# CEC1712H_S2_SX register map
Vendor: Microchip Technology; Series: CEC1712H_S2_SX; File version: 0
CPU: CM4 r1p0, little endian, no MPU, 3 interrupt priority bits, 172 interrupts
Registers are 32-bit, read-write, reset 0x0 unless marked. A register's access mark holds for its fields unless they carry their own. Offsets are from the block's base; [hi:lo] are bit positions.

## VCI — The VBAT-Powered Control Interfaces with the RTC With Date and DST Adjustment as well as the Week Alarm.
Base 0x4000AE00; register names take the prefix VCI_
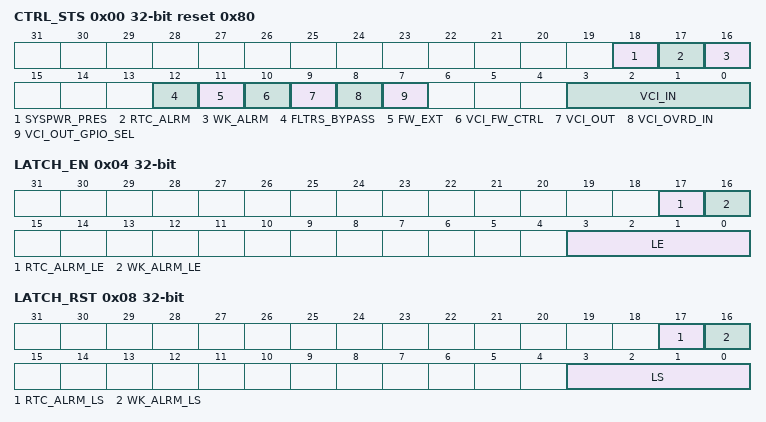
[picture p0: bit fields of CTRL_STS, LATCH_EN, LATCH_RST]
0x00 CTRL_STS reset 0x80 — VCI Register
  [18] SYSPWR_PRES — This is the System power present select bit. 1= VCI_IN3 is used as System power present. 0= VCI_IN3 is used as VCI_IN3.
  [17] RTC_ALRM — If enabled by RTC_ALRM_LE, this bit is set to 1 if the RTC Alarm signal is asserted. It is reset by writes to RTC_ALRM_LS.
  [16] WK_ALRM — If enabled by WEEK_ALRM_LE, this bit is set to 1 if the Week Alarm signal is asserted. It is reset by writes to WEEK_ALRM_LS.
  [12] FLTRS_BYPASS — The Filters Bypass bit is used to enable and disable the input filters on the VCI_IN# pins. 1=Filters disabled; 0=Filters enabled (default).
  [11] FW_EXT — This bit controls selecting between the external VBAT-Powered Control Interface inputs, or the VCI_FW_CNTRL bit output to control the VCI_OUT pin. 1=VCI_OUT is determined by the VCI_FW_CNTRL field, when VTR is active. 0=VCI_OUT is determined by the external inputs. Note: This bit used to be called GPO/nEXT. The name was changed to distinguish it from the BGPOs, which are elsewhere, and to remove a / in a bit name.
  [10] VCI_FW_CTRL — This bit can allow EC firmware to control the state of the VCI_OUT pin. For example, when VTR_PWRGD is asserted and the. FW_EXT bit is 1, clearing the VCI_FW_CNTRL bit de-asserts the active high VCI_OUT pin. BIOS must set this bit to 1 prior to setting the FW_EXT bit to 1 on power up, in order to avoid glitches on the VCI_OUT pin.
  [9] VCI_OUT — This bit provides the current status of the VCI_OUT pin.
  [8] VCI_OVRD_IN — This bit provides the current status of the VCI_OVRD_IN pin. Note: The VCI_OVRD_IN bit defaults to the state of the respective input pin.
  [7] VCI_OUT_GPIO_SEL — This bit selects the power source for GPIO outputs. 1= GPIO will be powered by VBAT power well (VCI_OUT functionality). 0= GPIO will be powered by VTR power well.
  [3:0] VCI_IN — These bits provide the latched state of the associated VCI_IN# pin, if latching is enabled or the current state of the pin if latching is not enabled. In both cases, the value is determined after the action of the VCI Polarity Register. Note: The VCI_IN[6:0]# bits default to the state of their respective input pins.
0x04 LATCH_EN — Latch Enable Register
  [17] RTC_ALRM_LE — Latch enable for the RTC Power-Up signal. 1=Enabled. Assertions of the RTC Alarm are held until the latch is reset by writing the corresponding LS bit. 0=Not Enabled. The RTC Alarm signal is not latched but passed directly to the VCI_OUT logic
  [16] WK_ALRM_LE — Latch enable for the Week Alarm Power-Up signal. 1=Enabled. Assertions of the Week Alarm are held until the latch is reset by writing the corresponding LS bit. 0=Not Enabled. The Week Alarm signal is not latched but passed directly to the VCI_OUT logic
  [3:0] LE — Latching Enables. Latching occurs after the Polarity configuration, so a VCI_INi# pin is asserted when it is '0' if VCI_IN_POL is '0', and asserted when it is '1' if VCI_IN_POL is '1'. For each bit in the field: 1=Enabled. Assertions of the VCI_INi# pin are held until the latch is reset by writing the corresponding LS bit. 0=Not Enabled. The VCI_INi# signal is not latched but passed directly to the VCI_OUT logic
0x08 LATCH_RST — Latch Resets Register
  [17] RTC_ALRM_LS — RTC Alarm Latch Reset. When this bit is written with a '1', the RTC Alarm Event latch is reset. The RTC Alarm input to the latch has priority over the Reset input Reads of this register are undefined.
  [16] WK_ALRM_LS — Week Alarm Latch Reset. When this bit is written with a '1', the Week Alarm Event latch is reset. The Week Alarm input to the latch has priority over the Reset input Reads of this register are undefined.
  [3:0] LS — Latch Resets. When a Latch Resets bit is written with a '1', the corresponding VCI_INi# latch is de-asserted ('1'). The VCI_INi# input to the latch has priority over the Latch Reset input, so firmware cannot reset the latch while the VCI_INi# pin is asserted. Firmware should sample the state of the pin in the VCI Register before attempting to reset the latch. As noted in the Latch Enable Register, the assertion level is determined by the VCI_IN_POL bit. Reads of this register are undefined.
0x0C INPUT_EN reset 0x7 — VCI Input Enable Register
  [3:0] IE — Input Enables for VCI_IN# signals. After changing the input enable for a VCI input, firmware should reset the input latch and clear any potential interrupt that may have been triggered by the input, as changing the enable may cause the internal status to change. For each bit in the field: 1=Enabled. The corresponding VCI_IN# input is not gated and toggling the pin will affect the VCI_OUT pin. 0=Not Enabled. the corresponding VCI_IN# input does not affect the VCI_OUT pin, even if the input is '0'. Unless the corresponding bit in the VCI Buffer Enable Register is 1, latches are not asserted, even if the VCI_IN# pin is low, during a VBAT power transition
0x10 HLDOFF_CNT — Holdoff Count Register
  [7:0] TIME — These bits determine the period of time the VCI_OUT logic is inhibited from re-asserting VCI_OUT after a SYS_SHDN# event. FFh-01h=The Power On Inhibit Holdoff Time is set to a period between 125ms and 31.875 seconds. 0=The Power On Inhibit function is disabled.
0x14 POLARITY — VCI Polarity Register
  [3:0] VCI_IN — These bits determine the polarity of the VCI_IN input signals: For each bit in the field: 1=Active High. The value on the pins is inverted before use. 0=Active Low (default).
0x18 PEDGE_DET — VCI Posedge Detect Register
  [3:0] VCI_IN — These bits record a low to high transition on the VCI_IN# pins. A 1 indicates a transition occurred. For each bit in the field: 1=Positive Edge Detected; 0=No edge detected.
0x1C NEDGE_DET — VCI Negedge Detect Register
  [3:0] VCI_IN — These bits record a high to low transition on the VCI_IN# pins. A 1 indicates a transition occurred. For each bit in the field: 1=Negative Edge Detected; 0=No edge detected.
0x20 BUFFER_EN — VCI Buffer Enable Register
  [3:0] V_BUF — Input Buffer enable. After changing the buffer enable for a VCI input, firmware should reset the input latch and clear any potential interrupt that may have been triggered by the input, as changing the buffer may cause the internal status to change. This register has no effect when VTR is powered. When VTR is on, the input buffers are enabled only by the IE bit. For each bit in the field: 1=VCI_IN# input buffer enabled independent of the IE bit. The edge detection latches for this input are always enabled. 0=VCI_IN# input buffer enabled by the IE bit. The edge detection latches are only enabled when the IE bit is 1 (default).
